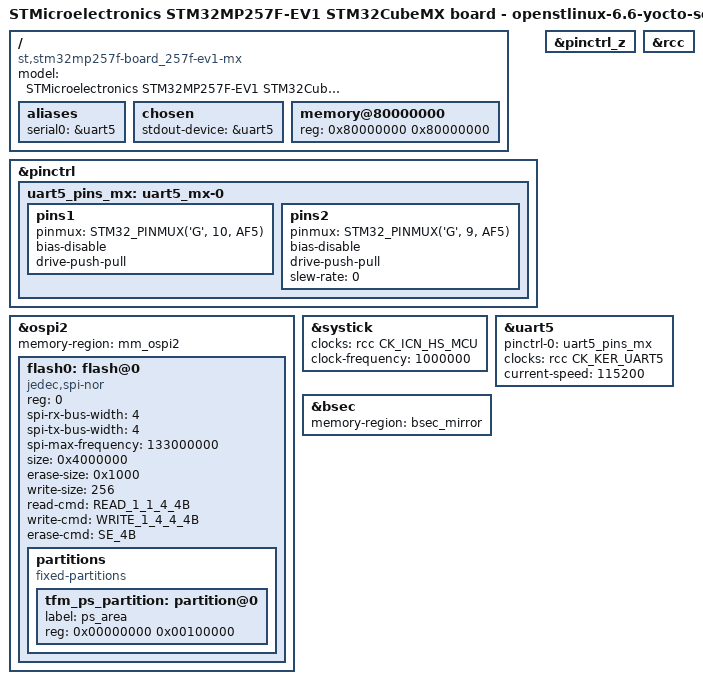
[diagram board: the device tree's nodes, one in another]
/dts-v1/;
#include "dt-bindings/clock/stm32mp25-clksrc.h"
#include "dt-bindings/reset/stm32mp25-resets.h"
#include <dt-bindings/pinctrl/stm32-pinfunc.h>
#include "stm32mp257.dtsi"
#include "stm32mp257f-board_257f-ev1-mx-rcc.dtsi"
#include "stm32mp257f-board_257f-ev1-mx-resmem.dtsi"
#include "stm32mp25xxai-pinctrl.dtsi"

/* USER CODE BEGIN includes */
#include <dt-bindings/clock/stm32mp25-clksrc.h>
#include <dt-bindings/reset/stm32mp25-resets.h>
/* USER CODE END includes */

/{
	model = "STMicroelectronics STM32MP257F-EV1 STM32CubeMX board - openstlinux-6.6-yocto-scarthgap-mpu-v24.11.06";
	compatible = "st,stm32mp257f-board_257f-ev1-mx", "st,stm32mp257f-ev1", "st,stm32mp257";

	/* USER CODE BEGIN root */

	aliases{
		serial0 = &uart5;
	};

	chosen{
		stdout-device = &uart5;
	};
	/* USER CODE END root */

	memory@80000000{
		device_type = "memory";
		reg = <0x80000000 0x80000000>;
	};
};

&pinctrl {

	uart5_pins_mx:uart5_mx-0{

		pins1{
			pinmux = <STM32_PINMUX('G', 10, AF5)>;
			bias-disable;
			drive-push-pull;
		};

		pins2{
			pinmux = <STM32_PINMUX('G', 9, AF5)>;
			bias-disable;
			drive-push-pull;
			slew-rate = <0>;
		};
	};
};

&pinctrl_z {
};

&ospi2 {
	status = "okay";

	/* USER CODE BEGIN ospi2 */
	memory-region = <&mm_ospi2>;
	#address-cells = <1>;
	#size-cells = <0>;

	flash0:flash@0{
		compatible = "jedec,spi-nor";
		reg = <0>;
		spi-rx-bus-width = <4>;
		spi-tx-bus-width = <4>;
		spi-max-frequency = <133000000>;
		size = <0x4000000>;
		erase-size = <0x1000>;
		write-size = <256>;
		read-cmd = "READ_1_1_4_4B";
		write-cmd = "WRITE_1_4_4_4B";
		erase-cmd = "SE_4B";

		partitions{
			compatible = "fixed-partitions";
			#address-cells = <1>;
			#size-cells = <1>;

			tfm_ps_partition:partition@0{
				label = "ps_area";
				reg = <0x00000000 0x00100000>;
			};
		};
	};
	/* USER CODE END ospi2 */
};

&rcc {
	status = "okay";
};

&systick {
	status = "okay";

	/* USER CODE BEGIN systick */
	clocks = <&rcc CK_ICN_HS_MCU>;
	clock-frequency = <1000000>;
	/* USER CODE END systick */
};

&uart5 {
	pinctrl-names = "default";
	pinctrl-0 = <&uart5_pins_mx>;
	status = "okay";

	/* USER CODE BEGIN uart5 */
	clocks = <&rcc CK_KER_UART5>;
	current-speed = <115200>;
	/* USER CODE END uart5 */
};

/* USER CODE BEGIN addons */

&bsec {
	memory-region = <&bsec_mirror>;
	status = "okay";
};
/* USER CODE END addons */
